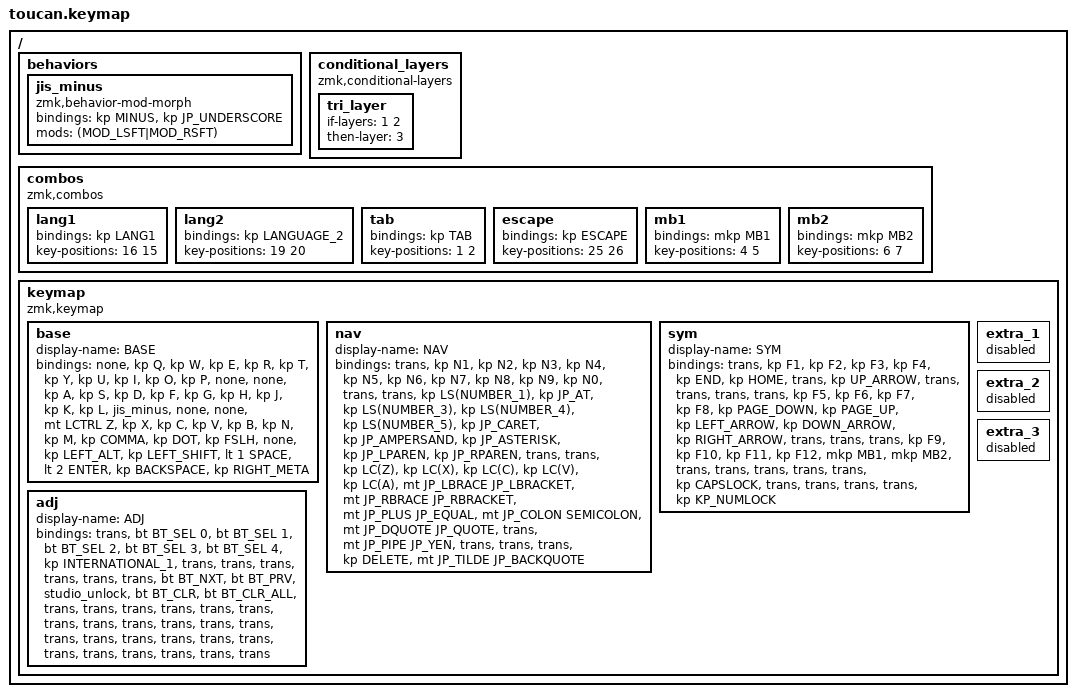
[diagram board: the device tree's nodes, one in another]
#include <behaviors.dtsi>
#include <dt-bindings/zmk/bt.h>
#include <dt-bindings/zmk/keys.h>
#include <dt-bindings/zmk/pointing.h>
#include <dt-bindings/zmk/modifiers.h>

#define BASE 0
#define NAV  1
#define SYM  2
#define ADJ  3

// ---- OS側をJIS(日本語キーボード)設定のまま使うための変換マクロ ----
// 左側 = キーマップ上で使う名前 / 右側 = 実際に送るUSキーコード / コメント = OS側で実際に出る文字

#define JP_DQUOTE       AT                // "
#define JP_AMPERSAND    CARET             // &
#define JP_QUOTE        AMPERSAND         // '
#define JP_EQUAL        UNDER             // =
#define JP_CARET        EQUAL             // ^
#define JP_YEN          0x89              // ¥ (バックスラッシュとしても使われる)
#define JP_PLUS         COLON             // +
#define JP_TILDE        PLUS              // ~
#define JP_PIPE         LS(0x89)          // |
#define JP_AT           LEFT_BRACKET      // @
#define JP_COLON        SINGLE_QUOTE      // :
#define JP_ASTERISK     DOUBLE_QUOTES     // *
#define JP_BACKQUOTE    LEFT_BRACE        // `
#define JP_UNDERSCORE   LS(0x87)          // _
#define JP_LBRACKET     RIGHT_BRACKET     // [
#define JP_RBRACKET     BACKSLASH         // ]
#define JP_LPAREN       ASTERISK          // (
#define JP_RPAREN       LEFT_PARENTHESIS  // )
#define JP_LBRACE       RIGHT_BRACE       // {
#define JP_RBRACE       PIPE              // }

/ {
    behaviors {
        // Shiftを押していない時は "-"、Shiftを押している時はJIS配列で "_" になる
        // ろ(INTERNATIONAL_1)+Shiftを送るキーコードに切り替える
        jis_minus: jis_minus {
            compatible = "zmk,behavior-mod-morph";
            #binding-cells = <0>;
            bindings = <&kp MINUS>, <&kp JP_UNDERSCORE>;
            mods = <(MOD_LSFT|MOD_RSFT)>;
        };
    };

    conditional_layers {
        compatible = "zmk,conditional-layers";

        tri_layer {
            if-layers = <1 2>;
            then-layer = <3>;
        };
    };

    combos {
        compatible = "zmk,combos";

        lang1 {
            bindings = <&kp LANG1>;
            key-positions = <16 15>;
        };

        lang2 {
            bindings = <&kp LANGUAGE_2>;
            key-positions = <19 20>;
        };

        tab {
            bindings = <&kp TAB>;
            key-positions = <1 2>;
        };

        escape {
            bindings = <&kp ESCAPE>;
            key-positions = <25 26>;
        };

        mb1 {
            bindings = <&mkp MB1>;
            key-positions = <4 5>;
        };

        mb2 {
            bindings = <&mkp MB2>;
            key-positions = <6 7>;
        };
    };

    keymap {
        compatible = "zmk,keymap";

        base {
            display-name = "BASE";
            bindings = <
&none  &kp Q  &kp W  &kp E  &kp R  &kp T  &kp Y  &kp U  &kp I  &kp O  &kp P  &none  &none  &kp A  &kp S  &kp D  &kp F  &kp G  &kp H  &kp J  &kp K  &kp L  &jis_minus  &none  &none  &mt LCTRL Z  &kp X  &kp C  &kp V  &kp B  &kp N  &kp M  &kp COMMA  &kp DOT  &kp FSLH  &none  &kp LEFT_ALT  &kp LEFT_SHIFT  &lt 1 SPACE  &lt 2 ENTER  &kp BACKSPACE  &kp RIGHT_META
            >;
        };

        nav {
            display-name = "NAV";
            bindings = <
&trans  &kp N1  &kp N2  &kp N3  &kp N4  &kp N5  &kp N6  &kp N7  &kp N8  &kp N9  &kp N0  &trans  &trans  &kp LS(NUMBER_1)  &kp JP_AT  &kp LS(NUMBER_3)  &kp LS(NUMBER_4)  &kp LS(NUMBER_5)  &kp JP_CARET  &kp JP_AMPERSAND  &kp JP_ASTERISK  &kp JP_LPAREN  &kp JP_RPAREN  &trans  &trans  &kp LC(Z)  &kp LC(X)  &kp LC(C)  &kp LC(V)  &kp LC(A)  &mt JP_LBRACE JP_LBRACKET  &mt JP_RBRACE JP_RBRACKET  &mt JP_PLUS JP_EQUAL  &mt JP_COLON SEMICOLON  &mt JP_DQUOTE JP_QUOTE  &trans  &mt JP_PIPE JP_YEN  &trans  &trans  &trans  &kp DELETE  &mt JP_TILDE JP_BACKQUOTE
            >;
        };

        sym {
            display-name = "SYM";
            bindings = <
&trans  &kp F1  &kp F2  &kp F3  &kp F4  &kp END  &kp HOME  &trans  &kp UP_ARROW  &trans  &trans  &trans  &trans  &kp F5  &kp F6  &kp F7  &kp F8  &kp PAGE_DOWN  &kp PAGE_UP  &kp LEFT_ARROW  &kp DOWN_ARROW  &kp RIGHT_ARROW  &trans  &trans  &trans  &kp F9  &kp F10  &kp F11  &kp F12  &mkp MB1  &mkp MB2  &trans  &trans  &trans  &trans  &trans  &kp CAPSLOCK  &trans  &trans  &trans  &trans  &kp KP_NUMLOCK
            >;
        };

        adj {
            display-name = "ADJ";
            bindings = <
&trans  &bt BT_SEL 0  &bt BT_SEL 1  &bt BT_SEL 2  &bt BT_SEL 3  &bt BT_SEL 4  &kp INTERNATIONAL_1  &trans  &trans  &trans  &trans  &trans  &trans  &bt BT_NXT  &bt BT_PRV  &studio_unlock  &bt BT_CLR  &bt BT_CLR_ALL  &trans  &trans  &trans  &trans  &trans  &trans  &trans  &trans  &trans  &trans  &trans  &trans  &trans  &trans  &trans  &trans  &trans  &trans  &trans  &trans  &trans  &trans  &trans  &trans
            >;
        };

        extra_1 { status = "reserved"; };
        extra_2 { status = "reserved"; };
        extra_3 { status = "reserved"; };
    };
};
